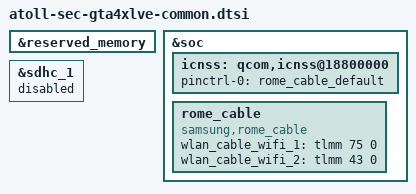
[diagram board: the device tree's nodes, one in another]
/* Copyright (c) 2020, The Linux Foundation. All rights reserved.
 *
 * This program is free software; you can redistribute it and/or modify
 * it under the terms of the GNU General Public License version 2 and
 * only version 2 as published by the Free Software Foundation.
 *
 * This program is distributed in the hope that it will be useful,
 * but WITHOUT ANY WARRANTY; without even the implied warranty of
 * MERCHANTABILITY or FITNESS FOR A PARTICULAR PURPOSE.  See the
 * GNU General Public License for more details.
 */


&reserved_memory {

};

&soc {
	icnss: qcom,icnss@18800000 {
		pinctrl-names = "default";
		pinctrl-0 = <&rome_cable_default>;
	};
	rome_cable {
		compatible = "samsung,rome_cable";
		wlan_cable_wifi_1 = <&tlmm 75 0>;
		wlan_cable_wifi_2 = <&tlmm 43 0>;
		status = "ok";
	};
};

&sdhc_1 {
	status = "disabled";
};
